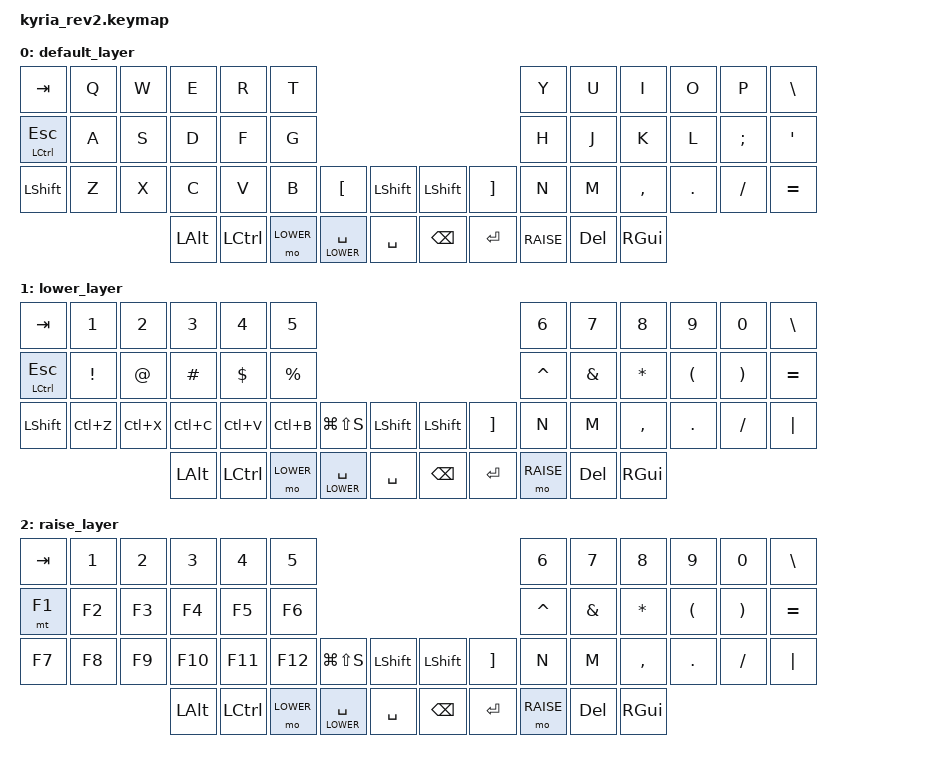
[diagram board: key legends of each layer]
/*
 * Copyright (c) 2020 The ZMK Contributors
 *
 * SPDX-License-Identifier: MIT
 */
#define DEFAULT 0
#define LOWER   1
#define RAISE   2

#include <behaviors.dtsi>
#include <dt-bindings/zmk/keys.h>

/ {
	keymap {
		compatible = "zmk,keymap";

		default_layer {
// ---------------------------------------------------------------------------------------------------------------------------------
// |  TAB         |  Q  |  W  |  E   |  R   |  T   |                                              |  Y    |  U    |  I    |  O    |   P   |   \   |
// | ESC/CTRL     |  A  |  S  |  D   |  F   |  G   |                                              |  H    |  J    |  K    |  L    |   ;   |   '   |
// | SHIFT        |  Z  |  X  |  C   |  V   |  B   | LBKT     | L SHIFT  |  | L SHIFT  |  RBKT    |  N    |  M    |  ,    |  .    |   /   | EQUAL |
//                            | LALT | LCTRL| RET  |  SPACE   |   SPACE  |  |   RET    |   RET    | TAB   | BSPC  | R-ALT |
			bindings =  < 
	&kp TAB       	&kp Q 		&kp W 		&kp E 		&kp R 		&kp T                 		                                  			&kp Y    	&kp U    	&kp I     	&kp O   	&kp P    	&kp BSLH
	&mt LCTRL ESC 	&kp A 		&kp S 		&kp D 		&kp F 		&kp G                 		                                  			&kp H    	&kp J    	&kp K     	&kp L   	&kp SEMI 	&kp SQT
	&kp LSHFT     	&kp Z 		&kp X 		&kp C 		&kp V 		&kp B     	&kp LBKT  		&kp LSHFT      &kp LSHFT &kp RBKT   			&kp N    	&kp M    	&kp COMMA 	&kp DOT 	&kp FSLH 	&kp EQUAL
	                    				    &kp LALT 	&kp LCTRL 	&mo LOWER   &lt LOWER SPACE &kp SPACE      &kp BSPC  &kp RET    			&kp RAISE 	&kp DEL  	&kp RGUI
			>;
		};

		lower_layer {
			bindings =  < 
	&kp TAB       	&kp N1 		&kp N2		&kp N3 		&kp N4 		&kp 5                                                   	    	&kp N6		&kp N7    	&kp N8		&kp N9  	&kp N0    	&kp BSLH
	&mt LCTRL ESC 	&kp EXCL 	&kp AT 		&kp HASH 	&kp DOLLAR 	&kp PERCENT                                                     	&kp CARET 	&kp AMPS  	&kp ASTRK 	&kp LPAR  	&kp RPAR 	&kp EQUAL
	&kp LSHFT     	&kp LC(Z) 	&kp LC(X)   &kp LC(C) 	&kp LC(V) 	&kp LC(B)   &kp LG(LS(S)) &kp LSHFT   		&kp LSHFT	&kp RBKT	&kp N    	&kp M    	&kp COMMA 	&kp DOT		&kp FSLH 	&kp PIPE
	                    					&kp LALT 	&kp LCTRL 	&mo LOWER  	&lt LOWER SPACE 	  &kp SPACE      	&kp BSPC  	&kp RET		&mo RAISE 	&kp DEL  	&kp RGUI
			>;
		};

		raise_layer {
			bindings =  < 
	&kp TAB       	&kp N1 		&kp N2		&kp N3 		&kp N4 		&kp 5                                                   	    	&kp N6		&kp N7    	&kp N8		&kp N9  	&kp N0    	&kp BSLH
	&mt F1	 		&kp F2 		&kp F3 		&kp F4 		&kp F5 		&kp F6                                                     	&kp CARET 	&kp AMPS  	&kp ASTRK 	&kp LPAR  	&kp RPAR 	&kp EQUAL
	&kp F7     		&kp F8 		&kp F9  	&kp F10 	&kp F11 	&kp F12   	&kp LG(LS(S)) &kp LSHFT   		&kp LSHFT	&kp RBKT	&kp N    	&kp M    	&kp COMMA 	&kp DOT		&kp FSLH 	&kp PIPE
	                    					&kp LALT 	&kp LCTRL 	&mo LOWER  	&lt LOWER SPACE 	  &kp SPACE      	&kp BSPC  	&kp RET		&mo RAISE 	&kp DEL  	&kp RGUI
			>;
		};



	};
};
